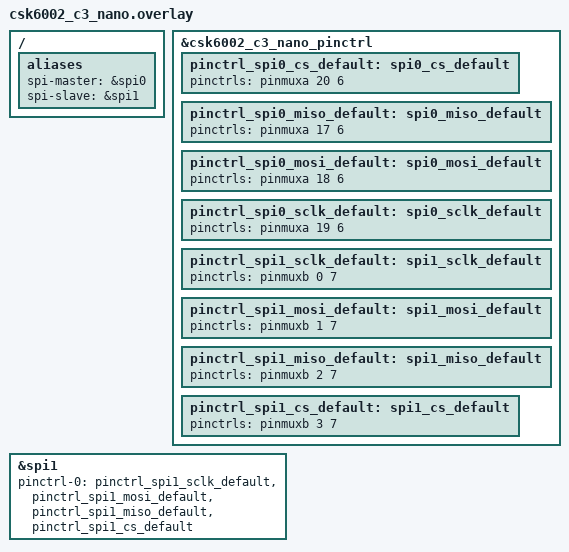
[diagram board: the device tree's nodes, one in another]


&csk6002_c3_nano_pinctrl{
            /* SPIC alternate function */
            pinctrl_spi0_cs_default: spi0_cs_default{
                    pinctrls = <&pinmuxa 20 6>;
            };

            pinctrl_spi0_miso_default: spi0_miso_default{
                    pinctrls = <&pinmuxa 17 6>;
            };

            pinctrl_spi0_mosi_default: spi0_mosi_default{
                    pinctrls = <&pinmuxa 18 6>;
            };

            pinctrl_spi0_sclk_default: spi0_sclk_default{
                    pinctrls = <&pinmuxa 19 6>;
            };
            
            pinctrl_spi1_sclk_default: spi1_sclk_default{
                    pinctrls = <&pinmuxb 0 7>;
            };
            
            pinctrl_spi1_mosi_default: spi1_mosi_default{
                    pinctrls = <&pinmuxb 1 7>;
            };

            pinctrl_spi1_miso_default: spi1_miso_default{
                    pinctrls = <&pinmuxb 2 7>;
            };    

            pinctrl_spi1_cs_default: spi1_cs_default{
                    pinctrls = <&pinmuxb 3 7>;
            };
            
};

&spi1{
    pinctrl-0 = <&pinctrl_spi1_sclk_default &pinctrl_spi1_mosi_default &pinctrl_spi1_miso_default &pinctrl_spi1_cs_default>; 
    pinctrl-names = "default";
    status = "okay";
};


/ {
     aliases {
        spi-master = &spi0;
        spi-slave = &spi1;
     };
};
